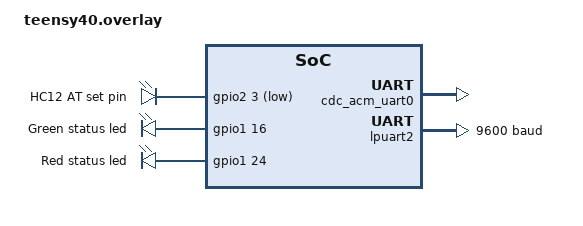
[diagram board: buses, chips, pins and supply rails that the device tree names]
/ {
    aliases {
        green-led = &green_led;
        red-led = &red_led;
        hc12 = &lpuart2;
        hc12-set = &hc12_set;
        usb = &cdc_acm_uart0;
     };
    
    pins {
        compatible = "gpio-leds";
        hc12_set: hc12_set {
            label = "HC12 AT set pin";
            gpios = <&gpio2 3 GPIO_ACTIVE_LOW>;
        };
        green_led: green_led {
            label = "Green status led";
            gpios = <&gpio1 16 GPIO_ACTIVE_HIGH>;
        };
        red_led: red_led {
            label = "Red status led";
            gpios = <&gpio1 24 GPIO_ACTIVE_HIGH>;
        };
    };
};

&zephyr_udc0 {
	cdc_acm_uart0: cdc_acm_uart0 {
		compatible = "zephyr,cdc-acm-uart";
		label = "CDC_ACM_0";
	};
};

&lpuart2 {
	status = "okay";
    current-speed = <9600>;
};
